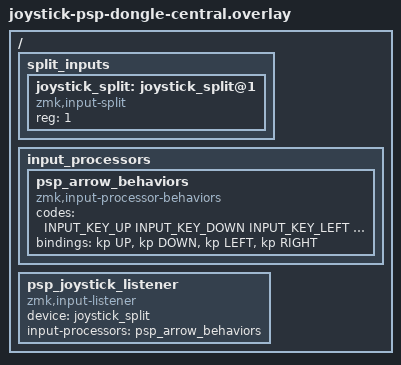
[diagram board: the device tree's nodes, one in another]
#include <dt-bindings/zmk/keys.h>
#include <zephyr/dt-bindings/input/input-event-codes.h>

/ {
    split_inputs {
        #address-cells = <1>;
        #size-cells = <0>;

        joystick_split: joystick_split@1 {
            compatible = "zmk,input-split";
            reg = <1>;
        };
    };

    input_processors {
        psp_arrow_behaviors: psp_arrow_behaviors {
            compatible = "zmk,input-processor-behaviors";
            #input-processor-cells = <0>;
            codes = <INPUT_KEY_UP INPUT_KEY_DOWN INPUT_KEY_LEFT INPUT_KEY_RIGHT>;
            bindings = <&kp UP &kp DOWN &kp LEFT &kp RIGHT>;
        };
    };

    psp_joystick_listener: psp_joystick_listener {
        compatible = "zmk,input-listener";
        device = <&joystick_split>;
        input-processors = <&psp_arrow_behaviors>;
    };
};
